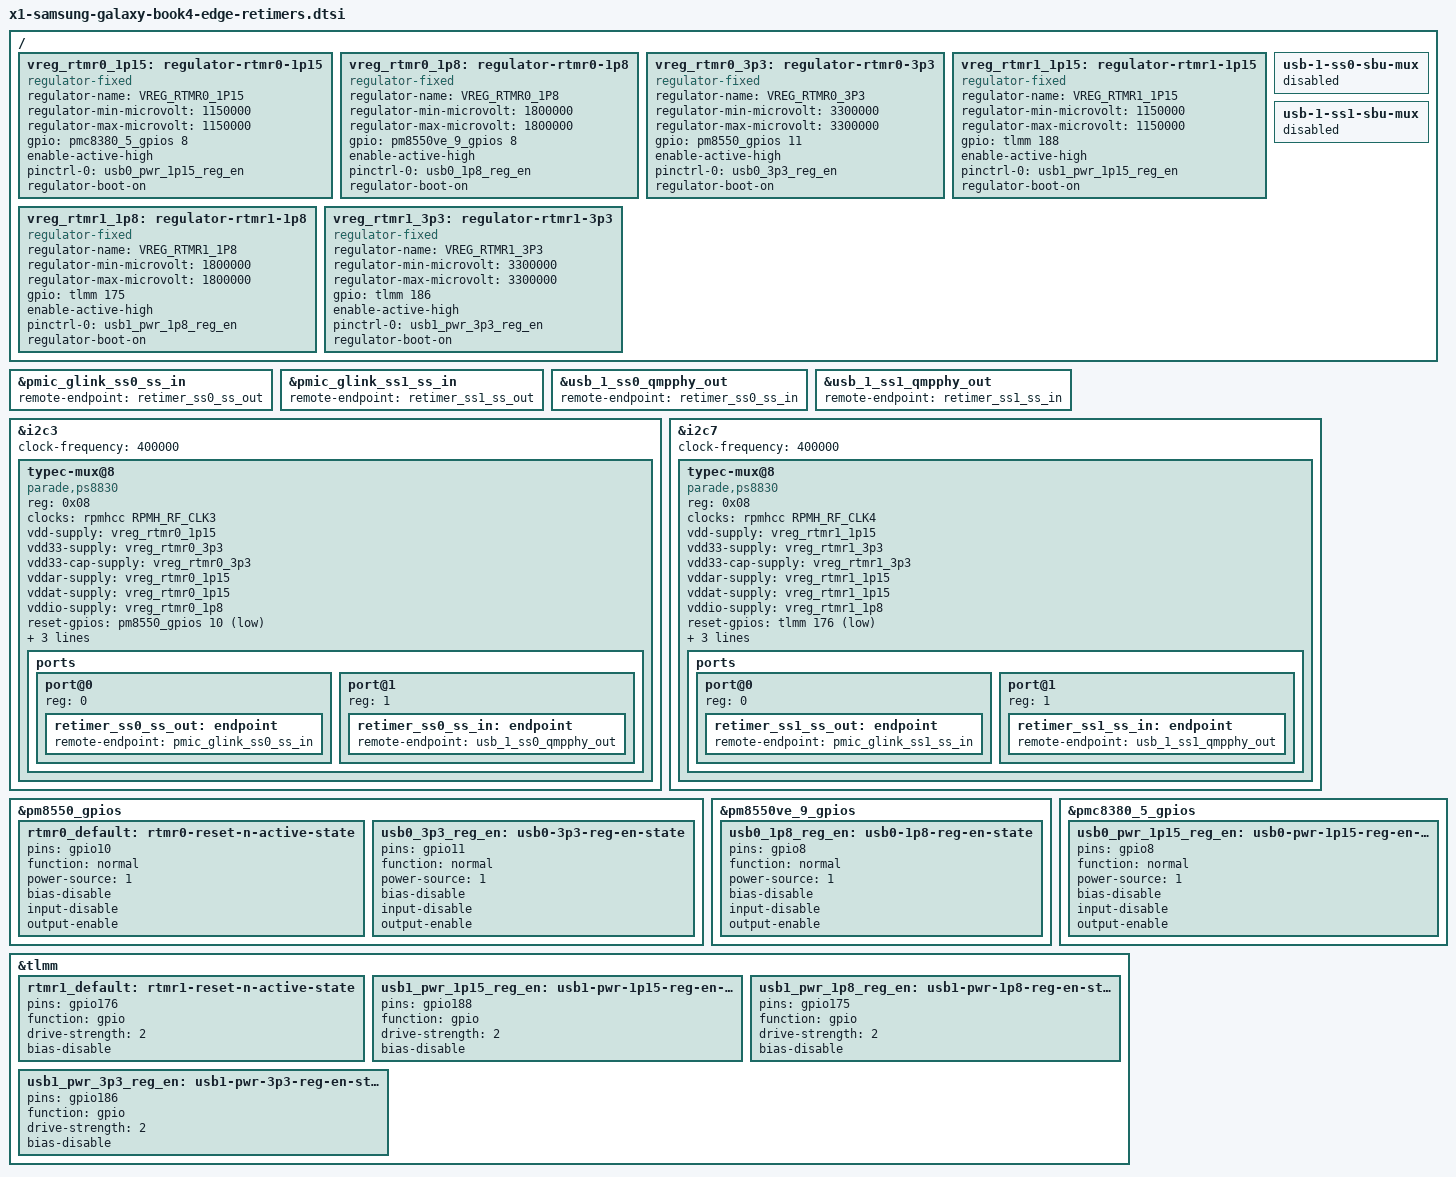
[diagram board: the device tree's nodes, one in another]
// SPDX-License-Identifier: BSD-3-Clause
/*
 * USB-C SuperSpeed for the Samsung Galaxy Book4 Edge: Parade PS8830 retimers.
 *
 * Ported from the 14" omarchy gb4e patch (retimer hunks only; the 14" speaker,
 * camera and EC hunks are not taken). ACPI UCS0 of the 15.6" (and of the CRD /
 * Yoga Slim 7x) puts the retimers at 0x08 on I2C4 and I2C8, which are Linux
 * i2c3 and i2c7, with the same enable and reset pins, so the 16" is assumed to
 * match. The SBU muxes are disabled: ACPI lists no SBU mux pins.
 *
 * The retimers only pass the SS lanes once something sets orientation and
 * mode; that is the gb4e_typec module plus the usbc service.
 */

/ {
	vreg_rtmr0_1p15: regulator-rtmr0-1p15 {
		compatible = "regulator-fixed";
		regulator-name = "VREG_RTMR0_1P15";
		regulator-min-microvolt = <1150000>;
		regulator-max-microvolt = <1150000>;
		gpio = <&pmc8380_5_gpios 8 GPIO_ACTIVE_HIGH>;
		enable-active-high;
		pinctrl-0 = <&usb0_pwr_1p15_reg_en>;
		pinctrl-names = "default";
		regulator-boot-on;
	};

	vreg_rtmr0_1p8: regulator-rtmr0-1p8 {
		compatible = "regulator-fixed";
		regulator-name = "VREG_RTMR0_1P8";
		regulator-min-microvolt = <1800000>;
		regulator-max-microvolt = <1800000>;
		gpio = <&pm8550ve_9_gpios 8 GPIO_ACTIVE_HIGH>;
		enable-active-high;
		pinctrl-0 = <&usb0_1p8_reg_en>;
		pinctrl-names = "default";
		regulator-boot-on;
	};

	vreg_rtmr0_3p3: regulator-rtmr0-3p3 {
		compatible = "regulator-fixed";
		regulator-name = "VREG_RTMR0_3P3";
		regulator-min-microvolt = <3300000>;
		regulator-max-microvolt = <3300000>;
		gpio = <&pm8550_gpios 11 GPIO_ACTIVE_HIGH>;
		enable-active-high;
		pinctrl-0 = <&usb0_3p3_reg_en>;
		pinctrl-names = "default";
		regulator-boot-on;
	};

	vreg_rtmr1_1p15: regulator-rtmr1-1p15 {
		compatible = "regulator-fixed";
		regulator-name = "VREG_RTMR1_1P15";
		regulator-min-microvolt = <1150000>;
		regulator-max-microvolt = <1150000>;
		gpio = <&tlmm 188 GPIO_ACTIVE_HIGH>;
		enable-active-high;
		pinctrl-0 = <&usb1_pwr_1p15_reg_en>;
		pinctrl-names = "default";
		regulator-boot-on;
	};

	vreg_rtmr1_1p8: regulator-rtmr1-1p8 {
		compatible = "regulator-fixed";
		regulator-name = "VREG_RTMR1_1P8";
		regulator-min-microvolt = <1800000>;
		regulator-max-microvolt = <1800000>;
		gpio = <&tlmm 175 GPIO_ACTIVE_HIGH>;
		enable-active-high;
		pinctrl-0 = <&usb1_pwr_1p8_reg_en>;
		pinctrl-names = "default";
		regulator-boot-on;
	};

	vreg_rtmr1_3p3: regulator-rtmr1-3p3 {
		compatible = "regulator-fixed";
		regulator-name = "VREG_RTMR1_3P3";
		regulator-min-microvolt = <3300000>;
		regulator-max-microvolt = <3300000>;
		gpio = <&tlmm 186 GPIO_ACTIVE_HIGH>;
		enable-active-high;
		pinctrl-0 = <&usb1_pwr_3p3_reg_en>;
		pinctrl-names = "default";
		regulator-boot-on;
	};

	usb-1-ss0-sbu-mux {
		status = "disabled";
	};

	usb-1-ss1-sbu-mux {
		status = "disabled";
	};
};

/* Route pmic_glink <-> retimer <-> QMP PHY instead of pmic_glink <-> QMP PHY */
&pmic_glink_ss0_ss_in {
	remote-endpoint = <&retimer_ss0_ss_out>;
};

&pmic_glink_ss1_ss_in {
	remote-endpoint = <&retimer_ss1_ss_out>;
};

&usb_1_ss0_qmpphy_out {
	remote-endpoint = <&retimer_ss0_ss_in>;
};

&usb_1_ss1_qmpphy_out {
	remote-endpoint = <&retimer_ss1_ss_in>;
};

/* USB-C port 0 retimer (ACPI UCS0, I2C4) */
&i2c3 {
	clock-frequency = <400000>;
	status = "okay";

	typec-mux@8 {
		compatible = "parade,ps8830";
		reg = <0x08>;
		clocks = <&rpmhcc RPMH_RF_CLK3>;
		vdd-supply = <&vreg_rtmr0_1p15>;
		vdd33-supply = <&vreg_rtmr0_3p3>;
		vdd33-cap-supply = <&vreg_rtmr0_3p3>;
		vddar-supply = <&vreg_rtmr0_1p15>;
		vddat-supply = <&vreg_rtmr0_1p15>;
		vddio-supply = <&vreg_rtmr0_1p8>;
		reset-gpios = <&pm8550_gpios 10 GPIO_ACTIVE_LOW>;
		pinctrl-0 = <&rtmr0_default>;
		pinctrl-names = "default";
		retimer-switch;
		orientation-switch;

		ports {
			#address-cells = <1>;
			#size-cells = <0>;

			port@0 {
				reg = <0>;
				retimer_ss0_ss_out: endpoint {
					remote-endpoint = <&pmic_glink_ss0_ss_in>;
				};
			};

			port@1 {
				reg = <1>;
				retimer_ss0_ss_in: endpoint {
					remote-endpoint = <&usb_1_ss0_qmpphy_out>;
				};
			};
		};
	};
};

/* USB-C port 1 retimer (ACPI UCS0, I2C8) */
&i2c7 {
	clock-frequency = <400000>;
	status = "okay";

	typec-mux@8 {
		compatible = "parade,ps8830";
		reg = <0x08>;
		clocks = <&rpmhcc RPMH_RF_CLK4>;
		vdd-supply = <&vreg_rtmr1_1p15>;
		vdd33-supply = <&vreg_rtmr1_3p3>;
		vdd33-cap-supply = <&vreg_rtmr1_3p3>;
		vddar-supply = <&vreg_rtmr1_1p15>;
		vddat-supply = <&vreg_rtmr1_1p15>;
		vddio-supply = <&vreg_rtmr1_1p8>;
		reset-gpios = <&tlmm 176 GPIO_ACTIVE_LOW>;
		pinctrl-0 = <&rtmr1_default>;
		pinctrl-names = "default";
		retimer-switch;
		orientation-switch;

		ports {
			#address-cells = <1>;
			#size-cells = <0>;

			port@0 {
				reg = <0>;
				retimer_ss1_ss_out: endpoint {
					remote-endpoint = <&pmic_glink_ss1_ss_in>;
				};
			};

			port@1 {
				reg = <1>;
				retimer_ss1_ss_in: endpoint {
					remote-endpoint = <&usb_1_ss1_qmpphy_out>;
				};
			};
		};
	};
};

&pm8550_gpios {
	rtmr0_default: rtmr0-reset-n-active-state {
		pins = "gpio10";
		function = "normal";
		power-source = <1>; /* 1.8V */
		bias-disable;
		input-disable;
		output-enable;
	};

	usb0_3p3_reg_en: usb0-3p3-reg-en-state {
		pins = "gpio11";
		function = "normal";
		power-source = <1>; /* 1.8V */
		bias-disable;
		input-disable;
		output-enable;
	};
};

&pm8550ve_9_gpios {
	usb0_1p8_reg_en: usb0-1p8-reg-en-state {
		pins = "gpio8";
		function = "normal";
		power-source = <1>; /* 1.8V */
		bias-disable;
		input-disable;
		output-enable;
	};
};

&pmc8380_5_gpios {
	usb0_pwr_1p15_reg_en: usb0-pwr-1p15-reg-en-state {
		pins = "gpio8";
		function = "normal";
		power-source = <1>; /* 1.8V */
		bias-disable;
		input-disable;
		output-enable;
	};
};

&tlmm {
	rtmr1_default: rtmr1-reset-n-active-state {
		pins = "gpio176";
		function = "gpio";
		drive-strength = <2>;
		bias-disable;
	};

	usb1_pwr_1p15_reg_en: usb1-pwr-1p15-reg-en-state {
		pins = "gpio188";
		function = "gpio";
		drive-strength = <2>;
		bias-disable;
	};

	usb1_pwr_1p8_reg_en: usb1-pwr-1p8-reg-en-state {
		pins = "gpio175";
		function = "gpio";
		drive-strength = <2>;
		bias-disable;
	};

	usb1_pwr_3p3_reg_en: usb1-pwr-3p3-reg-en-state {
		pins = "gpio186";
		function = "gpio";
		drive-strength = <2>;
		bias-disable;
	};
};
